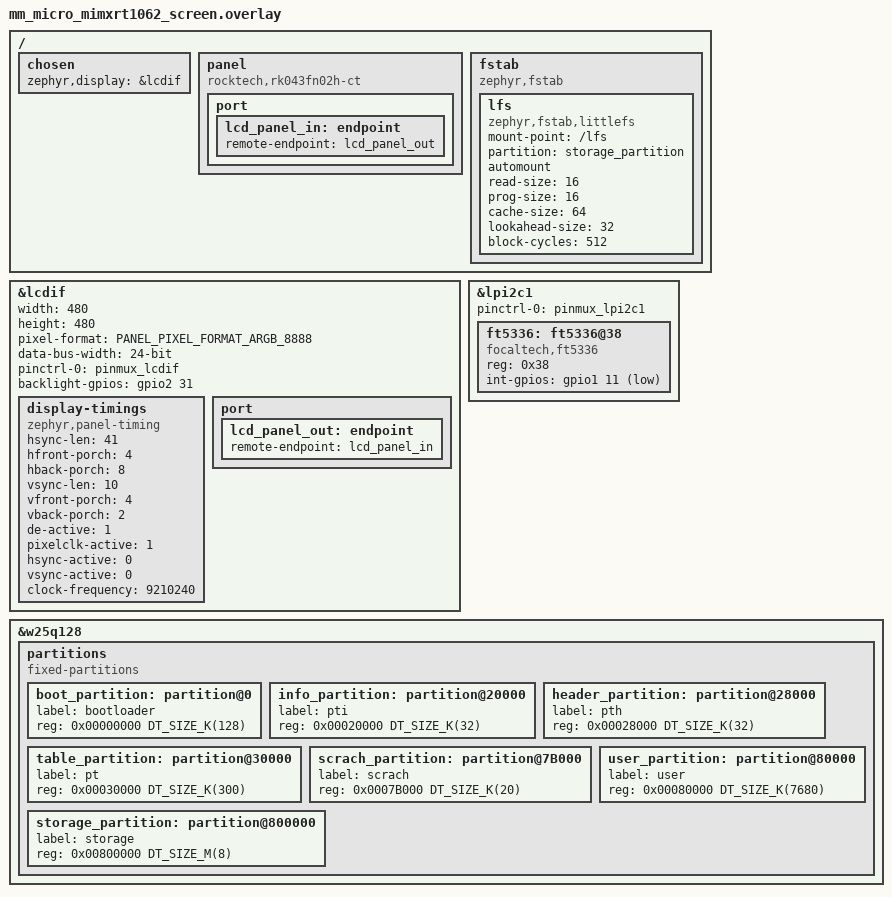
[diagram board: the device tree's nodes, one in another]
#include <zephyr/dt-bindings/display/panel.h>

/ {
	chosen {
		/*zephyr,flash = &sdram0;*/
		/delete-property/zephyr,flash;
		zephyr,display = &lcdif;
	};

	panel {
		compatible = "rocktech,rk043fn02h-ct";
		port {
			lcd_panel_in: endpoint {
				remote-endpoint = <&lcd_panel_out>;
			};
		};
	};

	fstab {
		compatible = "zephyr,fstab";
		lfs: lfs {
			compatible = "zephyr,fstab,littlefs";
			mount-point = "/lfs";
			partition = <&storage_partition>;
			automount;
			read-size = <16>;
			prog-size = <16>;
			cache-size = <64>;
			lookahead-size = <32>;
			block-cycles = <512>;
		};
	};

};

&lcdif {
	status = "okay";
	width = <480>;
	height = <480>;
	display-timings {
		compatible = "zephyr,panel-timing";
		hsync-len = <41>;
		hfront-porch = <4>;
		hback-porch = <8>;
		vsync-len = <10>;
		vfront-porch = <4>;
		vback-porch = <2>;
		de-active= <1>;
		pixelclk-active = <1>;
		hsync-active = <0>;
		vsync-active = <0>;
		clock-frequency = <9210240>;
	};
	pixel-format = <PANEL_PIXEL_FORMAT_ARGB_8888>;
	data-bus-width = "24-bit";
	pinctrl-0 = <&pinmux_lcdif>;
	pinctrl-names = "default";
	backlight-gpios = <&gpio2 31 GPIO_ACTIVE_HIGH>;
	port {
		lcd_panel_out: endpoint {
			remote-endpoint = <&lcd_panel_in>;
		};
	};
};

touch_i2c: &lpi2c1 {
	status = "okay";
	pinctrl-0 = <&pinmux_lpi2c1>;
	pinctrl-names = "default";

	ft5336: ft5336@38 {
		compatible = "focaltech,ft5336";
		reg = <0x38>;
		int-gpios = <&gpio1 11 GPIO_ACTIVE_LOW>;
	};
};

&w25q128 {
	partitions {
		compatible = "fixed-partitions";
		#address-cells = <1>;
		#size-cells = <1>;

		boot_partition: partition@0 {
			label = "bootloader";
			reg = <0x00000000 DT_SIZE_K(128)>;
		};

		info_partition: partition@20000 {
			label = "pti";
			reg = <0x00020000 DT_SIZE_K(32)>;
		};

		header_partition: partition@28000 {
			label = "pth";
			reg = <0x00028000 DT_SIZE_K(32)>;
		};

		table_partition: partition@30000 {
			label = "pt";
			reg = <0x00030000 DT_SIZE_K(300)>;
		};

		scrach_partition: partition@7B000 {
			label = "scrach";
			reg = <0x0007B000 DT_SIZE_K(20)>;
		};

		user_partition: partition@80000 {
			label = "user";
			reg = <0x00080000 DT_SIZE_K(7680)>;
		};

		storage_partition: partition@800000 {
			label = "storage";
			reg = <0x00800000 DT_SIZE_M(8)>;
		};
	};
};
